# ESP32-C6 register map
Vendor: ESPRESSIF SYSTEMS (SHANGHAI) CO., LTD.; Series: ESP32 C-Series; File version: 12
CPU: RV32IMAC r0p0, little endian, no MPU, no FPU, 0 interrupt priority bits
Address unit: 32 bits
Registers are 32-bit, read-write, reset 0x0 unless marked. A register's access mark holds for its fields unless they carry their own. Offsets are from the block's base; [hi:lo] are bit positions; lines under a group give offsets from that group; {n}, {i} and the like mark numbered series; 'fields as' and 'values as' point back to an identical list.

## HP_APM — HP_APM Peripheral
Base 0x60099000
0x00 REGION_FILTER_EN reset 0x1 — Region filter enable register
  [15:0] REGION_FILTER_EN — Region filter enable
{0x4+0xC*i} REGION{i} group (i=0..15) — Cluster REGION%s, containing REGION*_ADDR_START, REGION*_ADDR_END, REGION*_PMS_ATTR
  0x00 ADDR_START — Region address register
    [31:0] ADDR_START — Start address of region0
  0x04 ADDR_END reset 0xFFFFFFFF — Region address register
    [31:0] ADDR_END — End address of region0
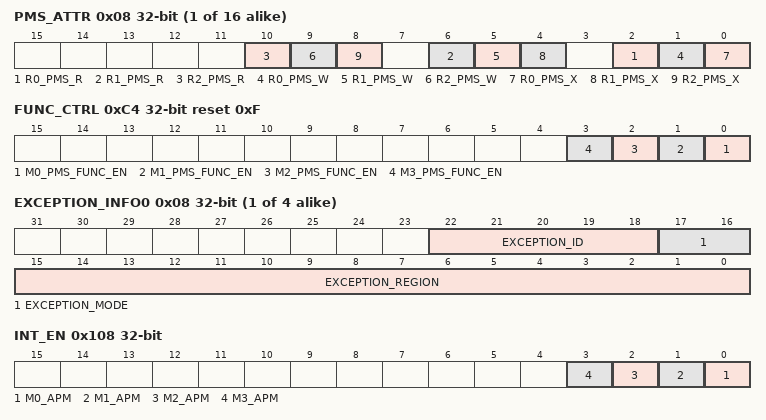
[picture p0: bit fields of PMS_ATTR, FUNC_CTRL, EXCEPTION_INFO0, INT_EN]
  0x08 PMS_ATTR — Region access authority attribute register
    [4n+2] R{n}_PMS_R (n=0..2) — Region read authority in REE_MODE{n}
    [4n+1] R{n}_PMS_W (n=0..2) — Region write authority in REE_MODE{n}
    [4n] R{n}_PMS_X (n=0..2) — Region execute authority in REE_MODE{n}
0xC4 FUNC_CTRL reset 0xF — PMS function control register
  [n] M{n}_PMS_FUNC_EN (n=0..3) — PMS M{n} function enable
{0xC8+0x10*i} M{i} group (i=0..3) — Cluster M%s, containing M?_STATUS, M?_STATUS_CLR, M?_EXCEPTION_INFO0, M?_EXCEPTION_INFO1
  0x00 STATUS ro — M0 status register
    [1:0] EXCEPTION_STATUS
  0x04 STATUS_CLR wo — M0 status clear register
    [0] REGION_STATUS_CLR — Clear exception status
  0x08 EXCEPTION_INFO0 ro — M0 exception_info0 register
    [22:18] EXCEPTION_ID — Exception id information
    [17:16] EXCEPTION_MODE
    [15:0] EXCEPTION_REGION
  0x0C EXCEPTION_INFO1 ro — M0 exception_info1 register
    [31:0] EXCEPTION_ADDR
0x108 INT_EN — APM interrupt enable register
  [n] M{n}_APM (n=0..3) — APM M{n} interrupt enable
0x10C CLOCK_GATE reset 0x1 — clock gating register
  [0] CLK_EN — reg_clk_en
0x7FC DATE — Version register

## LP_APM — Low-power Access Permission Management Controller
Base 0x600B3800
Registers as HP_APM, without REGION{n} (n=4..15), M2, M3, INT_EN, CLOCK_GATE, DATE; these are added or differ:
0x00 REGION_FILTER_EN reset 0x1 — Region filter enable register
  [3:0] REGION_FILTER_EN — Region filter enable
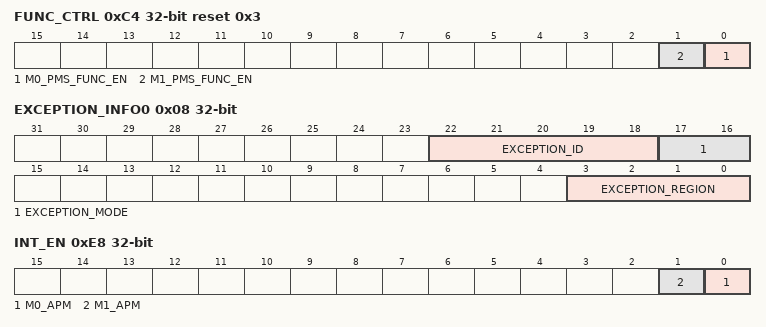
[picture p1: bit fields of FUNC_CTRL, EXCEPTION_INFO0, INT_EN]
0xC4 FUNC_CTRL reset 0x3 — PMS function control register
  [n] M{n}_PMS_FUNC_EN (n=0..1) — PMS M{n} function enable
0xC8 M0 group — Cluster M%s, containing M?_STATUS, M?_STATUS_CLR, M?_EXCEPTION_INFO0, M?_EXCEPTION_INFO1
  0x00 STATUS ro — M0 status register
    [1:0] EXCEPTION_STATUS
  0x04 STATUS_CLR wo — M0 status clear register
    [0] REGION_STATUS_CLR — Clear exception status
  0x08 EXCEPTION_INFO0 ro — M0 exception_info0 register
    [22:18] EXCEPTION_ID — Exception id information
    [17:16] EXCEPTION_MODE
    [3:0] EXCEPTION_REGION
  0x0C EXCEPTION_INFO1 ro — M0 exception_info1 register
    [31:0] EXCEPTION_ADDR
0xD8 M1 group — Cluster M%s, containing M?_STATUS, M?_STATUS_CLR, M?_EXCEPTION_INFO0, M?_EXCEPTION_INFO1
  0x00 STATUS ro — M0 status register
    [1:0] EXCEPTION_STATUS
  0x04 STATUS_CLR wo — M0 status clear register
    [0] REGION_STATUS_CLR — Clear exception status
  0x08 EXCEPTION_INFO0 ro — M0 exception_info0 register
    fields as M0.EXCEPTION_INFO0
  0x0C EXCEPTION_INFO1 ro — M0 exception_info1 register
    [31:0] EXCEPTION_ADDR
0xE8 INT_EN — APM interrupt enable register
  [n] M{n}_APM (n=0..1) — APM M{n} interrupt enable
0xEC CLOCK_GATE reset 0x1 — clock gating register
  [0] CLK_EN — reg_clk_en
0xFC DATE — Version register

## LP_APM0 — LP_APM0 Peripheral
Base 0x60099800
Registers as LP_APM, without M1, INT_EN, CLOCK_GATE, DATE; these are added or differ:
0xC4 FUNC_CTRL reset 0x1 — PMS function control register
  [n] M{n}_PMS_FUNC_EN (n=0..0) — PMS M{n} function enable
0xD8 INT_EN — APM interrupt enable register
  [n] M{n}_APM (n=0..0) — APM M{n} interrupt enable
0xDC CLOCK_GATE reset 0x1 — clock gating register
  [0] CLK_EN — reg_clk_en
0x7FC DATE — Version register
